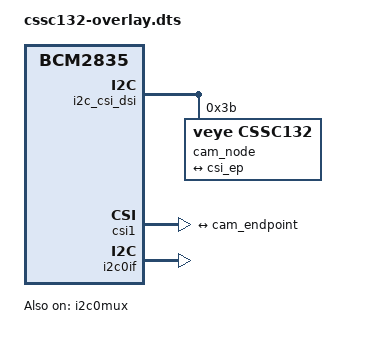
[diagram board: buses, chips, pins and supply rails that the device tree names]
// SPDX-License-Identifier: GPL-2.0-only
// Definitions for CS-MIPI-SC132 camera module on VC I2C bus
/dts-v1/;
/plugin/;

//#include <dt-bindings/gpio/gpio.h>

/{
	compatible = "brcm,bcm2835";

	i2c_frag: fragment@0 {
		target = <&i2c_csi_dsi>;
		__overlay__ {
			#address-cells = <1>;
			#size-cells = <0>;
			status = "okay";

			cam_node: cssc132@3b {
				compatible = "veye,cssc132";
				reg = <0x3b>;
				status = "okay";


		            rotation = <0>;
		            orientation = <2>;

				port {
					cam_endpoint: endpoint {
						remote-endpoint = <&csi_ep>;
						clock-lanes = <0>;
						data-lanes = <1 2>;
						clock-noncontinuous;
						link-frequencies =
							/bits/ 64 <297000000>;
					};
				};
			};
		};
	};

	csi_frag: fragment@1 {
		target = <&csi1>;
		csi: __overlay__ {
			status = "okay";
			brcm,media-controller;

			port {
				csi_ep: endpoint {
					remote-endpoint = <&cam_endpoint>;
					clock-lanes = <0>;
					data-lanes = <1 2>;
					clock-noncontinuous;
				};
			};
		};
	};
	
	fragment@2 {
		target = <&i2c0if>;
		__overlay__ {
			status = "okay";
		};
	};

	clk_frag: fragment@3 {
		target = <&cam1_clk>;
		__overlay__ {
			clock-frequency = <24000000>;
			status = "okay";
		};
	};

	fragment@4 {
		target = <&i2c0mux>;
		__overlay__ {
			status = "okay";
		};
	};

	__overrides__ {
		rotation = <&cam_node>,"rotation:0";
		orientation = <&cam_node>,"orientation:0";
		cam0 = <&i2c_frag>, "target:0=",<&i2c_csi_dsi0>,
		       <&csi_frag>, "target:0=",<&csi0>,
		       <&clk_frag>, "target:0=",<&cam0_clk>,
		       <&cam_node>, "clocks:0=",<&cam0_clk>,
		       <&cam_node>, "VANA-supply:0=",<&cam0_reg>;
	};
};

&cam_endpoint {
	remote-endpoint = <&csi_ep>;
};
